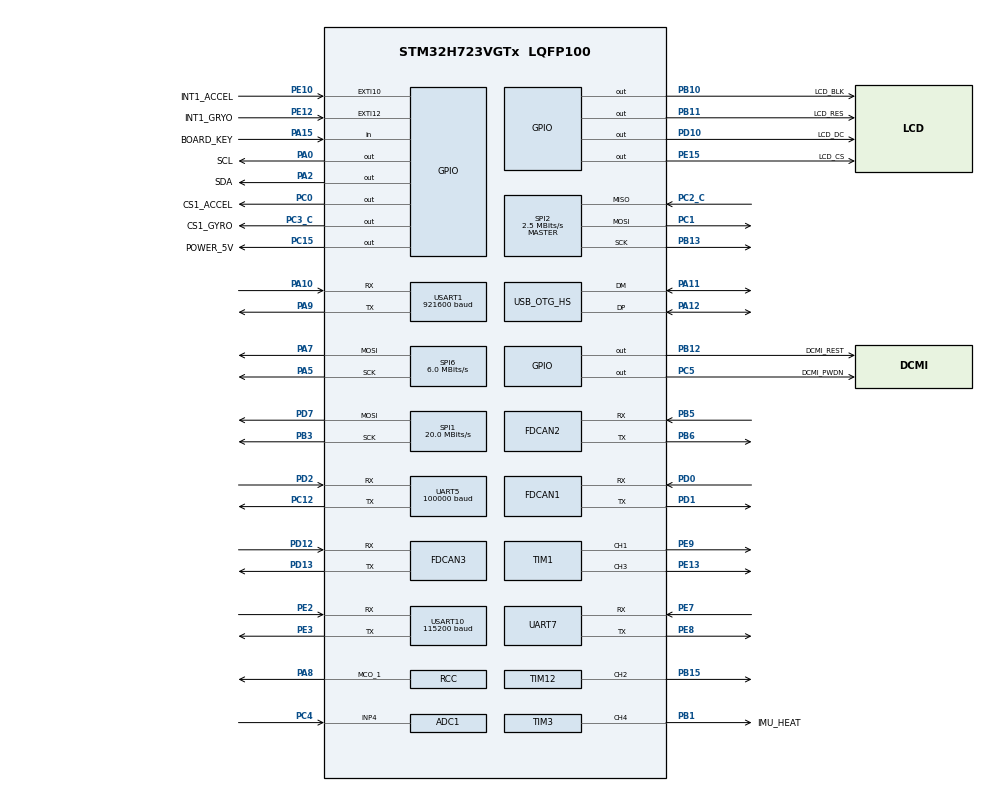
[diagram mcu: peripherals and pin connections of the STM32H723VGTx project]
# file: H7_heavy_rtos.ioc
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ADC1.Channel-0\#ChannelRegularConversion=ADC_CHANNEL_4
ADC1.ContinuousConvMode=ENABLE
ADC1.NbrOfConversionFlag=1
ADC1.OffsetNumber-0\#ChannelRegularConversion=ADC_OFFSET_NONE
ADC1.OffsetSignedSaturation-0\#ChannelRegularConversion=DISABLE
ADC1.Rank-0\#ChannelRegularConversion=1
ADC1.SamplingTime-0\#ChannelRegularConversion=ADC_SAMPLETIME_1CYCLE_5
ADC1.master=1
CORTEX_M7.default_mode_Activation=1
Dma.ADC1.6.Direction=DMA_PERIPH_TO_MEMORY
Dma.ADC1.6.EventEnable=DISABLE
Dma.ADC1.6.FIFOMode=DMA_FIFOMODE_DISABLE
Dma.ADC1.6.Instance=DMA2_Stream2
Dma.ADC1.6.MemDataAlignment=DMA_MDATAALIGN_HALFWORD
Dma.ADC1.6.MemInc=DMA_MINC_ENABLE
Dma.ADC1.6.Mode=DMA_NORMAL
Dma.ADC1.6.PeriphDataAlignment=DMA_PDATAALIGN_HALFWORD
Dma.ADC1.6.PeriphInc=DMA_PINC_DISABLE
Dma.ADC1.6.Polarity=HAL_DMAMUX_REQ_GEN_RISING
Dma.ADC1.6.Priority=DMA_PRIORITY_LOW
Dma.ADC1.6.RequestNumber=1
Dma.ADC1.6.SignalID=NONE
Dma.ADC1.6.SyncEnable=DISABLE
Dma.ADC1.6.SyncPolarity=HAL_DMAMUX_SYNC_NO_EVENT
Dma.ADC1.6.SyncRequestNumber=1
Dma.ADC1.6.SyncSignalID=NONE
Dma.Request0=USART1_RX
Dma.Request1=UART5_RX
Dma.Request2=USART10_RX
Dma.Request3=UART7_TX
Dma.Request4=SPI2_RX
Dma.Request5=SPI2_TX
Dma.Request6=ADC1
Dma.SPI2_RX.4.Direction=DMA_PERIPH_TO_MEMORY
Dma.SPI2_RX.4.EventEnable=DISABLE
Dma.SPI2_RX.4.FIFOMode=DMA_FIFOMODE_DISABLE
Dma.SPI2_RX.4.Instance=DMA2_Stream0
Dma.SPI2_RX.4.MemDataAlignment=DMA_MDATAALIGN_BYTE
Dma.SPI2_RX.4.MemInc=DMA_MINC_ENABLE
Dma.SPI2_RX.4.Mode=DMA_NORMAL
Dma.SPI2_RX.4.PeriphDataAlignment=DMA_PDATAALIGN_BYTE
Dma.SPI2_RX.4.PeriphInc=DMA_PINC_DISABLE
Dma.SPI2_RX.4.Polarity=HAL_DMAMUX_REQ_GEN_RISING
Dma.SPI2_RX.4.Priority=DMA_PRIORITY_VERY_HIGH
Dma.SPI2_RX.4.RequestNumber=1
Dma.SPI2_RX.4.SignalID=NONE
Dma.SPI2_RX.4.SyncEnable=DISABLE
Dma.SPI2_RX.4.SyncPolarity=HAL_DMAMUX_SYNC_NO_EVENT
Dma.SPI2_RX.4.SyncRequestNumber=1
Dma.SPI2_RX.4.SyncSignalID=NONE
Dma.SPI2_TX.5.Direction=DMA_MEMORY_TO_PERIPH
Dma.SPI2_TX.5.EventEnable=DISABLE
Dma.SPI2_TX.5.FIFOMode=DMA_FIFOMODE_DISABLE
Dma.SPI2_TX.5.Instance=DMA2_Stream1
Dma.SPI2_TX.5.MemDataAlignment=DMA_MDATAALIGN_BYTE
Dma.SPI2_TX.5.MemInc=DMA_MINC_ENABLE
Dma.SPI2_TX.5.Mode=DMA_NORMAL
Dma.SPI2_TX.5.PeriphDataAlignment=DMA_PDATAALIGN_BYTE
Dma.SPI2_TX.5.PeriphInc=DMA_PINC_DISABLE
Dma.SPI2_TX.5.Polarity=HAL_DMAMUX_REQ_GEN_RISING
Dma.SPI2_TX.5.Priority=DMA_PRIORITY_HIGH
Dma.SPI2_TX.5.RequestNumber=1
Dma.SPI2_TX.5.SignalID=NONE
Dma.SPI2_TX.5.SyncEnable=DISABLE
Dma.SPI2_TX.5.SyncPolarity=HAL_DMAMUX_SYNC_NO_EVENT
Dma.SPI2_TX.5.SyncRequestNumber=1
Dma.SPI2_TX.5.SyncSignalID=NONE
Dma.UART5_RX.1.Direction=DMA_PERIPH_TO_MEMORY
Dma.UART5_RX.1.EventEnable=DISABLE
Dma.UART5_RX.1.FIFOMode=DMA_FIFOMODE_DISABLE
Dma.UART5_RX.1.Instance=DMA1_Stream1
Dma.UART5_RX.1.MemDataAlignment=DMA_MDATAALIGN_BYTE
Dma.UART5_RX.1.MemInc=DMA_MINC_ENABLE
Dma.UART5_RX.1.Mode=DMA_NORMAL
Dma.UART5_RX.1.PeriphDataAlignment=DMA_PDATAALIGN_BYTE
Dma.UART5_RX.1.PeriphInc=DMA_PINC_DISABLE
Dma.UART5_RX.1.Polarity=HAL_DMAMUX_REQ_GEN_RISING
Dma.UART5_RX.1.Priority=DMA_PRIORITY_HIGH
Dma.UART5_RX.1.RequestNumber=1
Dma.UART5_RX.1.SignalID=NONE
Dma.UART5_RX.1.SyncEnable=DISABLE
Dma.UART5_RX.1.SyncPolarity=HAL_DMAMUX_SYNC_NO_EVENT
Dma.UART5_RX.1.SyncRequestNumber=1
Dma.UART5_RX.1.SyncSignalID=NONE
Dma.UART7_TX.3.Direction=DMA_MEMORY_TO_PERIPH
Dma.UART7_TX.3.EventEnable=DISABLE
Dma.UART7_TX.3.FIFOMode=DMA_FIFOMODE_DISABLE
Dma.UART7_TX.3.Instance=DMA1_Stream3
Dma.UART7_TX.3.MemDataAlignment=DMA_MDATAALIGN_BYTE
Dma.UART7_TX.3.MemInc=DMA_MINC_ENABLE
Dma.UART7_TX.3.Mode=DMA_NORMAL
Dma.UART7_TX.3.PeriphDataAlignment=DMA_PDATAALIGN_BYTE
Dma.UART7_TX.3.PeriphInc=DMA_PINC_DISABLE
Dma.UART7_TX.3.Polarity=HAL_DMAMUX_REQ_GEN_RISING
Dma.UART7_TX.3.Priority=DMA_PRIORITY_HIGH
Dma.UART7_TX.3.RequestNumber=1
Dma.UART7_TX.3.SignalID=NONE
Dma.UART7_TX.3.SyncEnable=DISABLE
Dma.UART7_TX.3.SyncPolarity=HAL_DMAMUX_SYNC_NO_EVENT
Dma.UART7_TX.3.SyncRequestNumber=1
Dma.UART7_TX.3.SyncSignalID=NONE
Dma.USART10_RX.2.Direction=DMA_PERIPH_TO_MEMORY
Dma.USART10_RX.2.EventEnable=DISABLE
Dma.USART10_RX.2.FIFOMode=DMA_FIFOMODE_DISABLE
Dma.USART10_RX.2.Instance=DMA1_Stream2
Dma.USART10_RX.2.MemDataAlignment=DMA_MDATAALIGN_BYTE
Dma.USART10_RX.2.MemInc=DMA_MINC_ENABLE
Dma.USART10_RX.2.Mode=DMA_NORMAL
Dma.USART10_RX.2.PeriphDataAlignment=DMA_PDATAALIGN_BYTE
Dma.USART10_RX.2.PeriphInc=DMA_PINC_DISABLE
Dma.USART10_RX.2.Polarity=HAL_DMAMUX_REQ_GEN_RISING
Dma.USART10_RX.2.Priority=DMA_PRIORITY_HIGH
Dma.USART10_RX.2.RequestNumber=1
Dma.USART10_RX.2.SignalID=NONE
Dma.USART10_RX.2.SyncEnable=DISABLE
Dma.USART10_RX.2.SyncPolarity=HAL_DMAMUX_SYNC_NO_EVENT
Dma.USART10_RX.2.SyncRequestNumber=1
Dma.USART10_RX.2.SyncSignalID=NONE
Dma.USART1_RX.0.Direction=DMA_PERIPH_TO_MEMORY
Dma.USART1_RX.0.EventEnable=DISABLE
Dma.USART1_RX.0.FIFOMode=DMA_FIFOMODE_DISABLE
Dma.USART1_RX.0.Instance=DMA1_Stream0
Dma.USART1_RX.0.MemDataAlignment=DMA_MDATAALIGN_BYTE
Dma.USART1_RX.0.MemInc=DMA_MINC_ENABLE
Dma.USART1_RX.0.Mode=DMA_NORMAL
Dma.USART1_RX.0.PeriphDataAlignment=DMA_PDATAALIGN_BYTE
Dma.USART1_RX.0.PeriphInc=DMA_PINC_DISABLE
Dma.USART1_RX.0.Polarity=HAL_DMAMUX_REQ_GEN_RISING
Dma.USART1_RX.0.Priority=DMA_PRIORITY_HIGH
Dma.USART1_RX.0.RequestNumber=1
Dma.USART1_RX.0.SignalID=NONE
Dma.USART1_RX.0.SyncEnable=DISABLE
Dma.USART1_RX.0.SyncPolarity=HAL_DMAMUX_SYNC_NO_EVENT
Dma.USART1_RX.0.SyncRequestNumber=1
Dma.USART1_RX.0.SyncSignalID=NONE
FDCAN1.AutoRetransmission=ENABLE
FDCAN1.CalculateBaudRateNominal=1000000
FDCAN1.CalculateTimeBitNominal=1000
FDCAN1.CalculateTimeQuantumNominal=12.5
FDCAN1.DataSyncJumpWidth=2
FDCAN1.DataTimeSeg1=13
FDCAN1.DataTimeSeg2=2
FDCAN1.FrameFormat=FDCAN_FRAME_FD_BRS
FDCAN1.NominalPrescaler=1
FDCAN1.NominalSyncJumpWidth=20
FDCAN1.NominalTimeSeg1=59
FDCAN1.NominalTimeSeg2=20
FDCAN1.ProtocolException=ENABLE
FDCAN1.RxBuffersNbr=2
FDCAN1.RxFifo0ElmtsNbr=10
FDCAN1.RxFifo1ElmtsNbr=10
FDCAN1.StdFiltersNbr=1
FDCAN1.TxBuffersNbr=10
FDCAN1.TxEventsNbr=10
FDCAN1.TxFifoQueueElmtsNbr=10
FDCAN2.AutoRetransmission=ENABLE
FDCAN2.CalculateBaudRateNominal=1000000
FDCAN2.CalculateTimeBitNominal=1000
FDCAN2.CalculateTimeQuantumNominal=12.5
FDCAN2.DataSyncJumpWidth=2
FDCAN2.DataTimeSeg1=13
FDCAN2.DataTimeSeg2=2
FDCAN2.FrameFormat=FDCAN_FRAME_FD_BRS
FDCAN2.MessageRAMOffset=1024
FDCAN2.NominalPrescaler=1
FDCAN2.NominalSyncJumpWidth=20
FDCAN2.NominalTimeSeg1=59
FDCAN2.NominalTimeSeg2=20
FDCAN2.ProtocolException=ENABLE
FDCAN2.RxBuffersNbr=2
FDCAN2.RxFifo0ElmtsNbr=10
FDCAN2.RxFifo1ElmtsNbr=10
FDCAN2.StdFiltersNbr=1
FDCAN2.TxBuffersNbr=10
FDCAN2.TxEventsNbr=10
FDCAN2.TxFifoQueueElmtsNbr=10
FDCAN3.AutoRetransmission=ENABLE
FDCAN3.CalculateBaudRateNominal=1000000
FDCAN3.CalculateTimeBitNominal=1000
FDCAN3.CalculateTimeQuantumNominal=12.5
FDCAN3.DataSyncJumpWidth=2
FDCAN3.DataTimeSeg1=13
FDCAN3.DataTimeSeg2=2
FDCAN3.FrameFormat=FDCAN_FRAME_FD_BRS
FDCAN3.MessageRAMOffset=2048
FDCAN3.NominalPrescaler=1
FDCAN3.NominalSyncJumpWidth=20
FDCAN3.NominalTimeSeg1=59
FDCAN3.NominalTimeSeg2=20
FDCAN3.ProtocolException=ENABLE
FDCAN3.RxBuffersNbr=2
FDCAN3.RxFifo0ElmtsNbr=10
FDCAN3.RxFifo1ElmtsNbr=10
FDCAN3.StdFiltersNbr=1
FDCAN3.TxBuffersNbr=10
FDCAN3.TxEventsNbr=10
FDCAN3.TxFifoQueueElmtsNbr=10
FREERTOS.Tasks01=InsTask,3,2048,StartInsTask,As weak,NULL,Dynamic,NULL,NULL;MotorTask,2,1024,StartMotorTask,As weak,NULL,Dynamic,NULL,NULL;ChassisTask,1,2048,StartChassisTask,As weak,NULL,Dynamic,NULL,NULL;GimbalTask,1,2048,StartGimbalTask,As weak,NULL,Dynamic,NULL,NULL;ShootTask,0,2048,StartShootTask,As weak,NULL,Dynamic,NULL,NULL;CmdTask,0,2048,StartCmdTask,As weak,NULL,Dynamic,NULL,NULL;UsartTask,0,2048,StartUsartTask,As weak,NULL,Dynamic,NULL,NULL;TransmissionTas,-1,2048,StartTransmissionTask,As weak,NULL,Dynamic,NULL,NULL;RefereeTask,-1,2048,StartRefereeTask,As weak,NULL,Dynamic,NULL,NULL;SpecialTask,-2,2048,StartSpecialTask,As weak,NULL,Dynamic,NULL,NULL;PowerTask,-2,1024,StartPowerTask,As weak,NULL,Dynamic,NULL,NULL
FREERTOS.configTOTAL_HEAP_SIZE=200000
FREERTOS.configUSE_COUNTING_SEMAPHORES=1
FREERTOS.configUSE_CO_ROUTINES=0
FREERTOS.configUSE_NEWLIB_REENTRANT=1
FREERTOS.configUSE_RECURSIVE_MUTEXES=1
FREERTOS.configUSE_TIMERS=1
FREERTOS.configUSE_TRACE_FACILITY=1
Mcu.Family=STM32H7
Mcu.Name=STM32H723VGTx
Mcu.Package=LQFP100
NVIC.DMA1_Stream0_IRQn=true\:5\:0\:false\:false\:true\:true\:false\:true\:true
NVIC.DMA1_Stream1_IRQn=true\:5\:0\:false\:false\:true\:true\:false\:true\:true
NVIC.DMA1_Stream2_IRQn=true\:5\:0\:false\:false\:true\:true\:false\:true\:true
NVIC.DMA1_Stream3_IRQn=true\:5\:0\:false\:false\:true\:true\:false\:true\:true
NVIC.DMA2_Stream0_IRQn=true\:5\:0\:true\:false\:true\:false\:false\:true\:true
NVIC.DMA2_Stream1_IRQn=true\:5\:0\:true\:false\:true\:false\:false\:true\:true
NVIC.DMA2_Stream2_IRQn=true\:5\:0\:true\:false\:true\:false\:false\:true\:true
NVIC.FDCAN1_IT0_IRQn=true\:5\:0\:true\:false\:true\:true\:true\:true\:true
NVIC.FDCAN1_IT1_IRQn=true\:5\:0\:true\:false\:true\:true\:true\:true\:true
NVIC.FDCAN2_IT0_IRQn=true\:5\:0\:true\:false\:true\:true\:true\:true\:true
NVIC.FDCAN2_IT1_IRQn=true\:5\:0\:true\:false\:true\:true\:true\:true\:true
NVIC.FDCAN3_IT0_IRQn=true\:5\:0\:true\:false\:true\:true\:true\:true\:true
NVIC.FDCAN3_IT1_IRQn=true\:5\:0\:true\:false\:true\:true\:true\:true\:true
NVIC.FDCAN_CAL_IRQn=true\:5\:0\:false\:false\:true\:true\:true\:true\:true
NVIC.OTG_HS_IRQn=true\:5\:0\:false\:false\:true\:true\:true\:true\:true
NVIC.PriorityGroup=NVIC_PRIORITYGROUP_4
NVIC.SPI2_IRQn=true\:5\:0\:false\:false\:true\:true\:false\:true\:true
NVIC.TIM23_IRQn=true\:15\:0\:false\:false\:true\:false\:false\:true\:true
NVIC.TimeBase=TIM23_IRQn
NVIC.TimeBaseIP=TIM23
NVIC.UART5_IRQn=true\:5\:0\:true\:false\:true\:true\:true\:true\:true
NVIC.UART7_IRQn=true\:5\:0\:true\:false\:true\:true\:true\:true\:true
NVIC.USART10_IRQn=true\:5\:0\:true\:false\:true\:true\:true\:true\:true
NVIC.USART1_IRQn=true\:5\:0\:true\:false\:true\:true\:true\:true\:true
PA0.GPIO_Label=SCL
PA0.Signal=GPIO_Output
PA10.GPIO_Speed=GPIO_SPEED_FREQ_VERY_HIGH
PA10.Mode=Asynchronous
PA10.Signal=USART1_RX
PA11.Mode=Device_Only_FS
PA11.Signal=USB_OTG_HS_DM
PA12.Mode=Device_Only_FS
PA12.Signal=USB_OTG_HS_DP
PA13(JTMS/SWDIO).Mode=Serial_Wire
PA13(JTMS/SWDIO).Signal=DEBUG_JTMS-SWDIO
PA14(JTCK/SWCLK).Mode=Serial_Wire
PA14(JTCK/SWCLK).Signal=DEBUG_JTCK-SWCLK
PA15(JTDI).GPIO_Label=BOARD_KEY
PA15(JTDI).Signal=GPIO_Input
PA2.GPIO_Label=SDA
PA2.Signal=GPIO_Output
PA5.GPIO_Speed=GPIO_SPEED_FREQ_HIGH
PA5.Mode=TX_Only_Simplex_Unidirect_Master
PA5.Signal=SPI6_SCK
PA7.GPIO_Speed=GPIO_SPEED_FREQ_HIGH
PA7.Mode=TX_Only_Simplex_Unidirect_Master
PA7.Signal=SPI6_MOSI
PA8.Mode=Clock-out-1
PA8.Signal=RCC_MCO_1
PA9.GPIO_Speed=GPIO_SPEED_FREQ_VERY_HIGH
PA9.Mode=Asynchronous
PA9.Signal=USART1_TX
PB1.GPIO_Label=IMU_HEAT
PB1.GPIO_PuPd=GPIO_PULLUP
PB1.GPIO_Speed=GPIO_SPEED_FREQ_VERY_HIGH
PB1.Signal=S_TIM3_CH4
PB10.GPIO_Label=LCD_BLK
PB10.GPIO_Speed=GPIO_SPEED_FREQ_HIGH
PB10.PinState=GPIO_PIN_RESET
PB10.Signal=GPIO_Output
PB11.GPIO_Label=LCD_RES
PB11.GPIO_Speed=GPIO_SPEED_FREQ_HIGH
PB11.Signal=GPIO_Output
PB12.GPIO_Label=DCMI_REST
PB12.GPIO_Speed=GPIO_SPEED_FREQ_VERY_HIGH
PB12.PinState=GPIO_PIN_SET
PB12.Signal=GPIO_Output
PB13.GPIO_Speed=GPIO_SPEED_FREQ_VERY_HIGH
PB13.Mode=Full_Duplex_Master
PB13.Signal=SPI2_SCK
PB15.Signal=S_TIM12_CH2
PB3(JTDO/TRACESWO).GPIO_Speed=GPIO_SPEED_FREQ_HIGH
PB3(JTDO/TRACESWO).Mode=TX_Only_Simplex_Unidirect_Master
PB3(JTDO/TRACESWO).Signal=SPI1_SCK
PB5.GPIO_Speed=GPIO_SPEED_FREQ_VERY_HIGH
PB5.Mode=FDCAN_Activate
PB5.Signal=FDCAN2_RX
PB6.GPIO_Speed=GPIO_SPEED_FREQ_VERY_HIGH
PB6.Mode=FDCAN_Activate
PB6.Signal=FDCAN2_TX
PB8.Signal=I2C1_SCL
PB9.Signal=I2C1_SDA
PC0.GPIO_Label=CS1_ACCEL
PC0.GPIO_Speed=GPIO_SPEED_FREQ_VERY_HIGH
PC0.PinState=GPIO_PIN_SET
PC0.Signal=GPIO_Output
PC1.GPIO_Speed=GPIO_SPEED_FREQ_VERY_HIGH
PC1.Mode=Full_Duplex_Master
PC1.Signal=SPI2_MOSI
PC12.GPIO_Speed=GPIO_SPEED_FREQ_VERY_HIGH
PC12.Mode=Asynchronous
PC12.Signal=UART5_TX
PC15-OSC32_OUT.GPIO_Label=POWER_5V
PC15-OSC32_OUT.PinState=GPIO_PIN_SET
PC15-OSC32_OUT.Signal=GPIO_Output
PC2_C.GPIO_Speed=GPIO_SPEED_FREQ_VERY_HIGH
PC2_C.Mode=Full_Duplex_Master
PC2_C.Signal=SPI2_MISO
PC3_C.GPIO_Label=CS1_GYRO
PC3_C.GPIO_Speed=GPIO_SPEED_FREQ_VERY_HIGH
PC3_C.PinState=GPIO_PIN_SET
PC3_C.Signal=GPIO_Output
PC4.Signal=ADCx_INP4
PC5.GPIO_Label=DCMI_PWDN
PC5.GPIO_Speed=GPIO_SPEED_FREQ_VERY_HIGH
PC5.PinState=GPIO_PIN_SET
PC5.Signal=GPIO_Output
PD0.GPIO_Speed=GPIO_SPEED_FREQ_VERY_HIGH
PD0.Mode=FDCAN_Activate
PD0.Signal=FDCAN1_RX
PD1.GPIO_Speed=GPIO_SPEED_FREQ_VERY_HIGH
PD1.Mode=FDCAN_Activate
PD1.Signal=FDCAN1_TX
PD10.GPIO_Label=LCD_DC
PD10.GPIO_Speed=GPIO_SPEED_FREQ_HIGH
PD10.Signal=GPIO_Output
PD12.GPIO_Speed=GPIO_SPEED_FREQ_VERY_HIGH
PD12.Mode=FDCAN_Activate
PD12.Signal=FDCAN3_RX
PD13.GPIO_Speed=GPIO_SPEED_FREQ_VERY_HIGH
PD13.Mode=FDCAN_Activate
PD13.Signal=FDCAN3_TX
PD2.GPIO_Speed=GPIO_SPEED_FREQ_VERY_HIGH
PD2.Mode=Asynchronous
PD2.Signal=UART5_RX
PD4.Signal=USART2_DE
PD5.Signal=USART2_TX
PD6.Signal=USART2_RX
PD7.GPIO_Speed=GPIO_SPEED_FREQ_HIGH
PD7.Mode=TX_Only_Simplex_Unidirect_Master
PD7.Signal=SPI1_MOSI
PE10.GPIO_Label=INT1_ACCEL
PE10.Signal=GPXTI10
PE12.GPIO_Label=INT1_GRYO
PE12.Signal=GPXTI12
PE13.Signal=S_TIM1_CH3
PE15.GPIO_Label=LCD_CS
PE15.GPIO_Speed=GPIO_SPEED_FREQ_HIGH
PE15.Signal=GPIO_Output
PE2.GPIO_Speed=GPIO_SPEED_FREQ_VERY_HIGH
PE2.Mode=Asynchronous
PE2.Signal=USART10_RX
PE3.GPIO_Speed=GPIO_SPEED_FREQ_VERY_HIGH
PE3.Mode=Asynchronous
PE3.Signal=USART10_TX
PE7.GPIO_Speed=GPIO_SPEED_FREQ_VERY_HIGH
PE7.Mode=Asynchronous
PE7.Signal=UART7_RX
PE8.GPIO_Speed=GPIO_SPEED_FREQ_VERY_HIGH
PE8.Mode=Asynchronous
PE8.Signal=UART7_TX
PE9.Signal=S_TIM1_CH1
PH0-OSC_IN.Mode=HSE-External-Oscillator
PH0-OSC_IN.Signal=RCC_OSC_IN
PH1-OSC_OUT.Mode=HSE-External-Oscillator
PH1-OSC_OUT.Signal=RCC_OSC_OUT
ProjectManager.HeapSize=0x2000
ProjectManager.StackSize=0x2000
ProjectManager.TargetToolchain=STM32CubeIDE
RCC.ADCFreq_Value=96000000
RCC.APB1Freq_Value=120000000
RCC.APB2Freq_Value=120000000
RCC.APB3Freq_Value=120000000
RCC.APB4Freq_Value=120000000
RCC.CortexFreq_Value=480000000
RCC.D1PPRE=RCC_APB3_DIV2
RCC.D2PPRE1=RCC_APB1_DIV2
RCC.D2PPRE2=RCC_APB2_DIV2
RCC.D3PPRE=RCC_APB4_DIV2
RCC.DIVM1=2
RCC.DIVM2=2
RCC.DIVM3=2
RCC.DIVN1=40
RCC.DIVN2=16
RCC.DIVN3=16
RCC.DIVP1=1
RCC.DIVQ1=6
RCC.HCLKFreq_Value=240000000
RCC.HPRE=RCC_HCLK_DIV2
RCC.HSE_VALUE=24000000
RCC.PLL2FRACN=0
RCC.PLL3FRACN=0
RCC.PLLFRACN=0
RCC.PLLSourceVirtual=RCC_PLLSOURCE_HSE
RCC.SPI6CLockSelection=RCC_SPI6CLKSOURCE_HSE
RCC.SYSCLKFreq_VALUE=480000000
RCC.SYSCLKSource=RCC_SYSCLKSOURCE_PLLCLK
RCC.USBCLockSelection=RCC_USBCLKSOURCE_HSI48
RCC.USBFreq_Value=48000000
SH.ADCx_INP4.0=ADC1_INP4,IN4-Single-Ended
SH.S_TIM12_CH2.0=TIM12_CH2,PWM Generation2 CH2
SH.S_TIM1_CH1.0=TIM1_CH1,Output Compare1 CH1
SH.S_TIM1_CH3.0=TIM1_CH3,Output Compare3 CH3
SH.S_TIM3_CH4.0=TIM3_CH4,PWM Generation4 CH4
SPI1.BaudRatePrescaler=SPI_BAUDRATEPRESCALER_4
SPI1.CLKPolarity=SPI_POLARITY_HIGH
SPI1.CalculateBaudRate=20.0 MBits/s
SPI1.DataSize=SPI_DATASIZE_8BIT
SPI1.Direction=SPI_DIRECTION_2LINES_TXONLY
SPI1.Mode=SPI_MODE_MASTER
SPI1.VirtualType=VM_MASTER
SPI2.BaudRatePrescaler=SPI_BAUDRATEPRESCALER_32
SPI2.CLKPhase=SPI_PHASE_2EDGE
SPI2.CLKPolarity=SPI_POLARITY_HIGH
SPI2.CalculateBaudRate=2.5 MBits/s
SPI2.DataSize=SPI_DATASIZE_8BIT
SPI2.Direction=SPI_DIRECTION_2LINES
SPI2.Mode=SPI_MODE_MASTER
SPI2.VirtualType=VM_MASTER
SPI6.BaudRatePrescaler=SPI_BAUDRATEPRESCALER_4
SPI6.CLKPhase=SPI_PHASE_2EDGE
SPI6.CLKPolarity=SPI_POLARITY_LOW
SPI6.CalculateBaudRate=6.0 MBits/s
SPI6.DataSize=SPI_DATASIZE_8BIT
SPI6.Direction=SPI_DIRECTION_2LINES_TXONLY
SPI6.Mode=SPI_MODE_MASTER
SPI6.VirtualType=VM_MASTER
STMicroelectronics.X-CUBE-ALGOBUILD.1.4.0.LibraryCcDSPOoLibraryJjDSPOoLibrary=true
TIM1.Channel-Output\ Compare1\ CH1=TIM_CHANNEL_1
TIM1.Channel-Output\ Compare3\ CH3=TIM_CHANNEL_3
TIM12.Channel-PWM\ Generation2\ CH2=TIM_CHANNEL_2
TIM3.Channel-PWM\ Generation4\ CH4=TIM_CHANNEL_4
UART5.BaudRate=100000
UART5.Parity=PARITY_EVEN
UART5.StopBits=UART_STOPBITS_1
UART5.WordLength=WORDLENGTH_9B
USART1.BaudRate=921600
USART1.VirtualMode-Asynchronous=VM_ASYNC
USART10.BaudRate=115200
USART10.VirtualMode=VM_ASYNC
USB_DEVICE.CLASS_NAME_HS=CDC
USB_DEVICE.VirtualMode=Cdc
USB_DEVICE.VirtualModeHS=Cdc_HS
USB_OTG_HS.VirtualMode-Device_Only_FS=Device_Only_FS
VP_FREERTOS_VS_CMSIS_V1.Mode=CMSIS_V1
VP_MEMORYMAP_VS_MEMORYMAP.Mode=CurAppReg
VP_STMicroelectronics.X-CUBE-ALGOBUILD_VS_DSPOoLibraryJjLibrary_1.4.0_1.4.0.Mode=DSPOoLibraryJjLibrary
VP_SYS_VS_tim23.Mode=TIM23
VP_TIM12_VS_ClockSourceINT.Mode=Internal
VP_TIM1_VS_ClockSourceINT.Mode=Internal
VP_TIM2_VS_ClockSourceINT.Mode=Internal
VP_TIM3_VS_ClockSourceINT.Mode=Internal
VP_USB_DEVICE_VS_USB_DEVICE_CDC_HS.Mode=CDC_HS
board=custom

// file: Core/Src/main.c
/* USER CODE BEGIN Header */
/**
  ******************************************************************************
  * @file           : main.c
  * @brief          : Main program body
  ******************************************************************************
  * @attention
  *
  * Copyright (c) 2026 STMicroelectronics.
  * All rights reserved.
  *
  * This software is licensed under terms that can be found in the LICENSE file
  * in the root directory of this software component.
  * If no LICENSE file comes with this software, it is provided AS-IS.
  *
  ******************************************************************************
  */
/* USER CODE END Header */
#include "main.h"
#include "cmsis_os.h"
#include "adc.h"
#include "dma.h"
#include "fdcan.h"
#include "spi.h"
#include "tim.h"
#include "usart.h"
#include "usb_device.h"
#include "gpio.h"

/* USER CODE BEGIN Includes */
#include "log_uart.h"
#include "board_power.h"
/* USER CODE END Includes */

void SystemClock_Config(void);
static void MPU_Config(void);
void MX_FREERTOS_Init(void);

int main(void)
{

  /* MPU Configuration--------------------------------------------------------*/
  MPU_Config();

  /* MCU Configuration--------------------------------------------------------*/

  /* Reset of all peripherals, Initializes the Flash interface and the Systick. */
  HAL_Init();

  /* Configure the system clock */
  SystemClock_Config();

  /* Initialize all configured peripherals */
  MX_GPIO_Init();
  /* 先使能对外 5V，再初始化 CAN 和遥控串口 */
  board_power_init();
  MX_DMA_Init();
  MX_FDCAN1_Init();
  MX_FDCAN2_Init();
  MX_FDCAN3_Init();
  MX_TIM1_Init();
  MX_TIM2_Init();
  MX_TIM3_Init();
  MX_UART5_Init();
  MX_UART7_Init();
  MX_USART10_UART_Init();
  MX_ADC1_Init();
  MX_SPI1_Init();
  MX_SPI2_Init();
  MX_SPI6_Init();
  MX_TIM12_Init();
  MX_USART1_UART_Init();
  /* USER CODE BEGIN 2 */
  /* printf 重定向到 UART7，需在 MX_UART7_Init 之后调用 */
  log_uart_init();
  printf("\r\n[BOOT] H7 heavy rtos start, build %s %s\r\n", __DATE__, __TIME__);
  /* USER CODE END 2 */

  /* Call init function for freertos objects (in cmsis_os2.c) */
  MX_FREERTOS_Init();

  /* Start scheduler */
  osKernelStart();

  /* We should never get here as control is now taken by the scheduler */

  /* Infinite loop */
  while (1)
  {

  }
}

void SystemClock_Config(void)
{
  RCC_OscInitTypeDef RCC_OscInitStruct = {0};
  RCC_ClkInitTypeDef RCC_ClkInitStruct = {0};

  /** Supply configuration update enable
  */
  HAL_PWREx_ConfigSupply(PWR_LDO_SUPPLY);

  /** Configure the main internal regulator output voltage
  */
  __HAL_PWR_VOLTAGESCALING_CONFIG(PWR_REGULATOR_VOLTAGE_SCALE0);

  while(!__HAL_PWR_GET_FLAG(PWR_FLAG_VOSRDY)) {}

  /** Initializes the RCC Oscillators according to the specified parameters
  * in the RCC_OscInitTypeDef structure.
  */
  RCC_OscInitStruct.OscillatorType = RCC_OSCILLATORTYPE_HSI48|RCC_OSCILLATORTYPE_HSI
                              |RCC_OSCILLATORTYPE_HSE;
  RCC_OscInitStruct.HSEState = RCC_HSE_ON;
  RCC_OscInitStruct.HSIState = RCC_HSI_DIV1;
  RCC_OscInitStruct.HSICalibrationValue = 64;
  RCC_OscInitStruct.HSI48State = RCC_HSI48_ON;
  RCC_OscInitStruct.PLL.PLLState = RCC_PLL_ON;
  RCC_OscInitStruct.PLL.PLLSource = RCC_PLLSOURCE_HSE;
  RCC_OscInitStruct.PLL.PLLM = 2;
  RCC_OscInitStruct.PLL.PLLN = 40;
  RCC_OscInitStruct.PLL.PLLP = 1;
  RCC_OscInitStruct.PLL.PLLQ = 6;
  RCC_OscInitStruct.PLL.PLLR = 2;
  RCC_OscInitStruct.PLL.PLLRGE = RCC_PLL1VCIRANGE_3;
  RCC_OscInitStruct.PLL.PLLVCOSEL = RCC_PLL1VCOWIDE;
  RCC_OscInitStruct.PLL.PLLFRACN = 0;
  if (HAL_RCC_OscConfig(&RCC_OscInitStruct) != HAL_OK)
  {
    Error_Handler();
  }

  /** Initializes the CPU, AHB and APB buses clocks
  */
  RCC_ClkInitStruct.ClockType = RCC_CLOCKTYPE_HCLK|RCC_CLOCKTYPE_SYSCLK
                              |RCC_CLOCKTYPE_PCLK1|RCC_CLOCKTYPE_PCLK2
                              |RCC_CLOCKTYPE_D3PCLK1|RCC_CLOCKTYPE_D1PCLK1;
  RCC_ClkInitStruct.SYSCLKSource = RCC_SYSCLKSOURCE_PLLCLK;
  RCC_ClkInitStruct.SYSCLKDivider = RCC_SYSCLK_DIV1;
  RCC_ClkInitStruct.AHBCLKDivider = RCC_HCLK_DIV2;
  RCC_ClkInitStruct.APB3CLKDivider = RCC_APB3_DIV2;
  RCC_ClkInitStruct.APB1CLKDivider = RCC_APB1_DIV2;
  RCC_ClkInitStruct.APB2CLKDivider = RCC_APB2_DIV2;
  RCC_ClkInitStruct.APB4CLKDivider = RCC_APB4_DIV2;

  if (HAL_RCC_ClockConfig(&RCC_ClkInitStruct, FLASH_LATENCY_3) != HAL_OK)
  {
    Error_Handler();
  }
  HAL_RCC_MCOConfig(RCC_MCO1, RCC_MCO1SOURCE_HSI, RCC_MCODIV_1);
}

 /* MPU Configuration */

void MPU_Config(void)
{
  MPU_Region_InitTypeDef MPU_InitStruct = {0};

  /* Disables the MPU */
  HAL_MPU_Disable();

  /** Initializes and configures the Region and the memory to be protected
  */
  MPU_InitStruct.Enable = MPU_REGION_ENABLE;
  MPU_InitStruct.Number = MPU_REGION_NUMBER0;
  MPU_InitStruct.BaseAddress = 0x0;
  MPU_InitStruct.Size = MPU_REGION_SIZE_4GB;
  MPU_InitStruct.SubRegionDisable = 0x87;
  MPU_InitStruct.TypeExtField = MPU_TEX_LEVEL0;
  MPU_InitStruct.AccessPermission = MPU_REGION_NO_ACCESS;
  MPU_InitStruct.DisableExec = MPU_INSTRUCTION_ACCESS_DISABLE;
  MPU_InitStruct.IsShareable = MPU_ACCESS_SHAREABLE;
  MPU_InitStruct.IsCacheable = MPU_ACCESS_NOT_CACHEABLE;
  MPU_InitStruct.IsBufferable = MPU_ACCESS_NOT_BUFFERABLE;

  HAL_MPU_ConfigRegion(&MPU_InitStruct);
  /* Enables the MPU */
  HAL_MPU_Enable(MPU_PRIVILEGED_DEFAULT);

}

void HAL_TIM_PeriodElapsedCallback(TIM_HandleTypeDef *htim)
{
  if (htim->Instance == TIM23)
  {
    HAL_IncTick();
  }
}

void Error_Handler(void)
{
  __disable_irq();
  while (1)
  {
  }
}

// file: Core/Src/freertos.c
/* USER CODE BEGIN Header */
/**
  ******************************************************************************
  * File Name          : freertos.c
  * Description        : Code for freertos applications
  ******************************************************************************
  * @attention
  *
  * Copyright (c) 2026 STMicroelectronics.
  * All rights reserved.
  *
  * This software is licensed under terms that can be found in the LICENSE file
  * in the root directory of this software component.
  * If no LICENSE file comes with this software, it is provided AS-IS.
  *
  ******************************************************************************
  */
/* USER CODE END Header */

#include "FreeRTOS.h"
#include "task.h"
#include "main.h"
#include "cmsis_os.h"

osThreadId InsTaskHandle;
osThreadId MotorTaskHandle;
osThreadId ChassisTaskHandle;
osThreadId GimbalTaskHandle;
osThreadId ShootTaskHandle;
osThreadId CmdTaskHandle;
osThreadId UsartTaskHandle;
osThreadId TransmissionTasHandle;
osThreadId RefereeTaskHandle;
osThreadId SpecialTaskHandle;
osThreadId PowerTaskHandle;

void StartInsTask(void const * argument);
void StartMotorTask(void const * argument);
void StartChassisTask(void const * argument);
void StartGimbalTask(void const * argument);
void StartShootTask(void const * argument);
void StartCmdTask(void const * argument);
void StartUsartTask(void const * argument);
void StartTransmissionTask(void const * argument);
void StartRefereeTask(void const * argument);
void StartSpecialTask(void const * argument);
void StartPowerTask(void const * argument);

extern void MX_USB_DEVICE_Init(void);
void MX_FREERTOS_Init(void); /* (MISRA C 2004 rule 8.1) */

/* GetIdleTaskMemory prototype (linked to static allocation support) */
void vApplicationGetIdleTaskMemory( StaticTask_t **ppxIdleTaskTCBBuffer, StackType_t **ppxIdleTaskStackBuffer, uint32_t *pulIdleTaskStackSize );

/* GetTimerTaskMemory prototype (linked to static allocation support) */
void vApplicationGetTimerTaskMemory( StaticTask_t **ppxTimerTaskTCBBuffer, StackType_t **ppxTimerTaskStackBuffer, uint32_t *pulTimerTaskStackSize );

/* USER CODE BEGIN GET_IDLE_TASK_MEMORY */
static StaticTask_t xIdleTaskTCBBuffer;
static StackType_t xIdleStack[configMINIMAL_STACK_SIZE];

void vApplicationGetIdleTaskMemory( StaticTask_t **ppxIdleTaskTCBBuffer, StackType_t **ppxIdleTaskStackBuffer, uint32_t *pulIdleTaskStackSize )
{
  *ppxIdleTaskTCBBuffer = &xIdleTaskTCBBuffer;
  *ppxIdleTaskStackBuffer = &xIdleStack[0];
  *pulIdleTaskStackSize = configMINIMAL_STACK_SIZE;
  /* place for user code */
}
/* USER CODE END GET_IDLE_TASK_MEMORY */

/* USER CODE BEGIN GET_TIMER_TASK_MEMORY */
static StaticTask_t xTimerTaskTCBBuffer;
static StackType_t xTimerStack[configTIMER_TASK_STACK_DEPTH];

void vApplicationGetTimerTaskMemory( StaticTask_t **ppxTimerTaskTCBBuffer, StackType_t **ppxTimerTaskStackBuffer, uint32_t *pulTimerTaskStackSize )
{
  *ppxTimerTaskTCBBuffer = &xTimerTaskTCBBuffer;
  *ppxTimerTaskStackBuffer = &xTimerStack[0];
  *pulTimerTaskStackSize = configTIMER_TASK_STACK_DEPTH;
  /* place for user code */
}
/* USER CODE END GET_TIMER_TASK_MEMORY */

void MX_FREERTOS_Init(void) {

  /* Create the thread(s) */
  /* definition and creation of InsTask */
  osThreadDef(InsTask, StartInsTask, osPriorityRealtime, 0, 2048);
  InsTaskHandle = osThreadCreate(osThread(InsTask), NULL);

  /* definition and creation of MotorTask */
  osThreadDef(MotorTask, StartMotorTask, osPriorityHigh, 0, 1024);
  MotorTaskHandle = osThreadCreate(osThread(MotorTask), NULL);

  /* definition and creation of ChassisTask */
  osThreadDef(ChassisTask, StartChassisTask, osPriorityAboveNormal, 0, 2048);
  ChassisTaskHandle = osThreadCreate(osThread(ChassisTask), NULL);

  /* definition and creation of GimbalTask */
  osThreadDef(GimbalTask, StartGimbalTask, osPriorityAboveNormal, 0, 2048);
  GimbalTaskHandle = osThreadCreate(osThread(GimbalTask), NULL);

  /* definition and creation of ShootTask */
  osThreadDef(ShootTask, StartShootTask, osPriorityNormal, 0, 2048);
  ShootTaskHandle = osThreadCreate(osThread(ShootTask), NULL);

  /* definition and creation of CmdTask */
  osThreadDef(CmdTask, StartCmdTask, osPriorityNormal, 0, 2048);
  CmdTaskHandle = osThreadCreate(osThread(CmdTask), NULL);

  /* definition and creation of UsartTask */
  osThreadDef(UsartTask, StartUsartTask, osPriorityNormal, 0, 2048);
  UsartTaskHandle = osThreadCreate(osThread(UsartTask), NULL);

  /* definition and creation of TransmissionTas */
  osThreadDef(TransmissionTas, StartTransmissionTask, osPriorityBelowNormal, 0, 2048);
  TransmissionTasHandle = osThreadCreate(osThread(TransmissionTas), NULL);

  /* definition and creation of RefereeTask */
  osThreadDef(RefereeTask, StartRefereeTask, osPriorityBelowNormal, 0, 2048);
  RefereeTaskHandle = osThreadCreate(osThread(RefereeTask), NULL);

  /* definition and creation of SpecialTask */
  osThreadDef(SpecialTask, StartSpecialTask, osPriorityLow, 0, 2048);
  SpecialTaskHandle = osThreadCreate(osThread(SpecialTask), NULL);

  /* definition and creation of PowerTask */
  osThreadDef(PowerTask, StartPowerTask, osPriorityLow, 0, 1024);
  PowerTaskHandle = osThreadCreate(osThread(PowerTask), NULL);

}

__weak void StartInsTask(void const * argument)
{
  /* init code for USB_DEVICE */
  MX_USB_DEVICE_Init();
  for(;;)
  {
    osDelay(1);
  }
}

__weak void StartMotorTask(void const * argument)
{
  for(;;)
  {
    osDelay(1);
  }
}

__weak void StartChassisTask(void const * argument)
{
  for(;;)
  {
    osDelay(1);
  }
}

__weak void StartGimbalTask(void const * argument)
{
  for(;;)
  {
    osDelay(1);
  }
}

__weak void StartShootTask(void const * argument)
{
  for(;;)
  {
    osDelay(1);
  }
}

__weak void StartCmdTask(void const * argument)
{
  for(;;)
  {
    osDelay(1);
  }
}

__weak void StartUsartTask(void const * argument)
{
  for(;;)
  {
    osDelay(1);
  }
}

__weak void StartTransmissionTask(void const * argument)
{
  for(;;)
  {
    osDelay(1);
  }
}

__weak void StartRefereeTask(void const * argument)
{
  for(;;)
  {
    osDelay(1);
  }
}

__weak void StartSpecialTask(void const * argument)
{
  for(;;)
  {
    osDelay(1);
  }
}

__weak void StartPowerTask(void const * argument)
{
  for(;;)
  {
    osDelay(1);
  }
}
